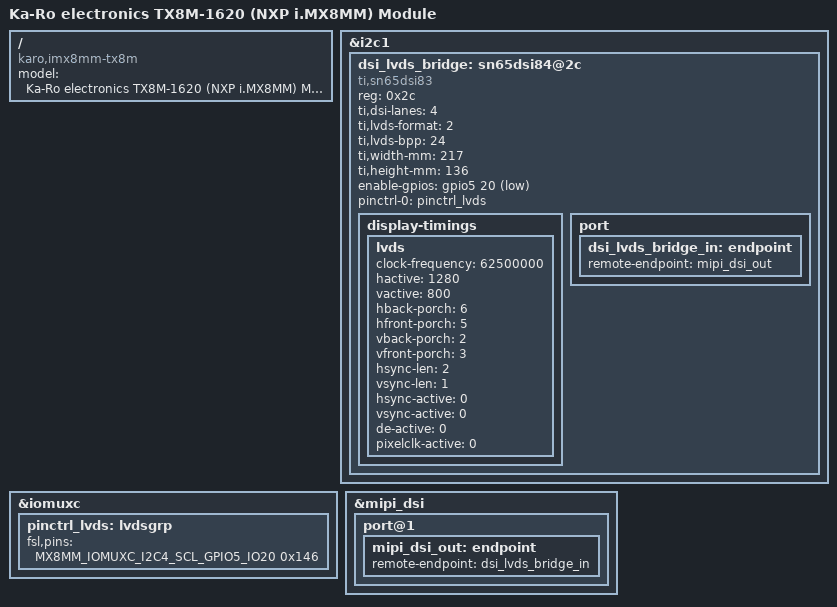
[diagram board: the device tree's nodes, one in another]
// SPDX-License-Identifier: (GPL-2.0 OR MIT)
/*
 * Copyright (C) 2019 Markus Bauer <MB@KARO-electronics.de>
 *
 */

/dts-v1/;

#include "imx8mm-tx8m-16xx.dtsi"
#include <dt-bindings/input/input.h>

/ {
	model = "Ka-Ro electronics TX8M-1620 (NXP i.MX8MM) Module";
	compatible = "karo,imx8mm-tx8m", "fsl,imx8mm";
};

&i2c1 {
        dsi_lvds_bridge: sn65dsi84@2c {
                compatible = "ti,sn65dsi83";
                reg = <0x2c>;
                ti,dsi-lanes = <4>;
                ti,lvds-format = <2>;
                ti,lvds-bpp = <24>;
                ti,width-mm = <217>;
                ti,height-mm = <136>;
                enable-gpios = <&gpio5 20 GPIO_ACTIVE_LOW>;
                pinctrl-names = "default";
                pinctrl-0 = <&pinctrl_lvds>;
                status = "okay";

                display-timings {
                        lvds {
                                clock-frequency = <62500000>;
                                hactive = <1280>;
                                vactive = <800>;
                                hback-porch = <6>;
                                hfront-porch = <5>;
                                vback-porch = <2>;
                                vfront-porch = <3>;
                                hsync-len = <2>;
                                vsync-len = <1>;
                                hsync-active = <0>;
                                vsync-active = <0>;
                                de-active = <0>;
                                pixelclk-active = <0>;
                        };
                };

                port {
                        dsi_lvds_bridge_in: endpoint {
                                remote-endpoint = <&mipi_dsi_out>;
                        };
                };
        };
};

&iomuxc {
        pinctrl_lvds: lvdsgrp {
		fsl,pins = <
			MX8MM_IOMUXC_I2C4_SCL_GPIO5_IO20		0x146
		>;
	};
};

&mipi_dsi {
	status = "okay";

        port@1 {
		mipi_dsi_out: endpoint {
			remote-endpoint = <&dsi_lvds_bridge_in>;
		};
	};
};
